# max32655 register map
Vendor: Maxim-Integrated; Series: ARMCM4; File version: 1.1
CPU: CM4 r2p1, little endian, MPU, FPU, 3 interrupt priority bits
Registers are 32-bit, read-write, reset 0x0 unless marked. A register's access mark holds for its fields unless they carry their own. Offsets are from the block's base; [hi:lo] are bit positions; {n}, {i} and the like mark numbered series.

## PT — Pulse Train
Base 0x4003C020
Same registers: PT1 0x4003C040, PT2 0x4003C060, PT3 0x4003C080
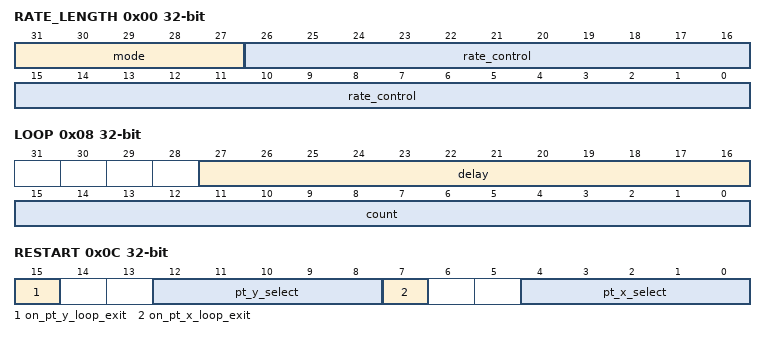
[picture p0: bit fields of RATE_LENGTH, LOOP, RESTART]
0x00 RATE_LENGTH — Pulse Train Configuration
  [31:27] mode — Pulse Train Output Mode/Train Length
    0=32_BIT (Pulse train, 32 bit pattern.); 1=SQUARE_WAVE (Square wave mode.); {v}={v}_BIT (Pulse train, {v} bit pattern.) (v=2..31)
  [26:0] rate_control — Pulse Train Enable and Rate Control. Set to 0 to disable the Pulse Train.
0x04 TRAIN — Write the repeating bit pattern that is shifted out, LSB first, when configured in Pulse Train mode. See PT_RATE_LENGTH.mode for setting the length.
0x08 LOOP — Pulse Train Loop Count
  [27:16] delay — Delay between loops of the Pulse Train in PT Peripheral Clock cycles
  [15:0] count — Number of loops for this pulse train to repeat.
0x0C RESTART — Pulse Train Auto-Restart Configuration.
  [15] on_pt_y_loop_exit — Enable Auto-Restart on PT Y Loop Exit
  [12:8] pt_y_select — Auto-Restart PT Y Select
  [7] on_pt_x_loop_exit — Enable Auto-Restart on PT X Loop Exit
  [4:0] pt_x_select — Auto-Restart PT X Select

## PTG — Pulse Train Generation
Base 0x4003C000
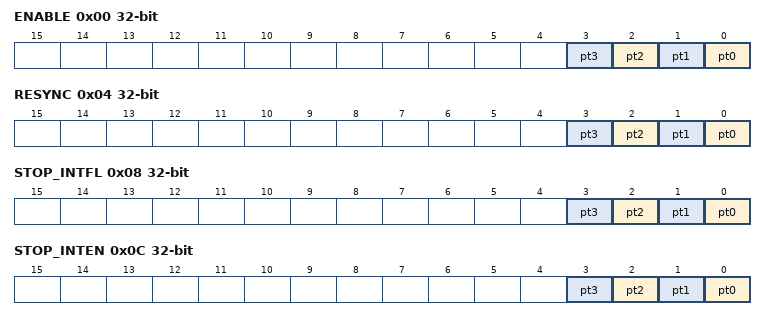
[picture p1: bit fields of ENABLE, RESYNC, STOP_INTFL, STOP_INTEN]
0x00 ENABLE — Global Enable/Disable Controls for All Pulse Trains
  [n] pt{n} (n=0..3) — Enable/Disable control for PT{n}
0x04 RESYNC — Global Resync (All Pulse Trains) Control
  [n] pt{n} (n=0..3) — Resync control for PT{n}
0x08 STOP_INTFL — Pulse Train Stop Interrupt Flags
  [n] pt{n} (n=0..3) — Pulse Train {n} Stopped Interrupt Flag
0x0C STOP_INTEN — Pulse Train Stop Interrupt Enable/Disable
  [n] pt{n} (n=0..3) — Pulse Train {n} Stopped Interrupt Enable/Disable
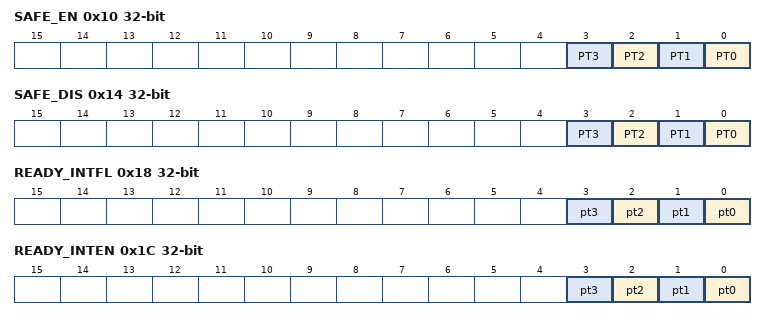
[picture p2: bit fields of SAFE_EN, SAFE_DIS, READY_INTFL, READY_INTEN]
0x10 SAFE_EN wo — Pulse Train Global Safe Enable.
  [n] PT{n} (n=0..3)
0x14 SAFE_DIS wo — Pulse Train Global Safe Disable.
  [n] PT{n} (n=0..3)
0x18 READY_INTFL — Pulse Train Ready Interrupt Flags
  [n] pt{n} (n=0..3) — Pulse Train {n} Ready Interrupt Flag
0x1C READY_INTEN — Pulse Train Ready Interrupt Enable/Disable
  [n] pt{n} (n=0..3) — Pulse Train {n} Ready Interrupt Enable/Disable

## PWRSEQ — Power Sequencer / Low Power Control Register.
Base 0x40006800
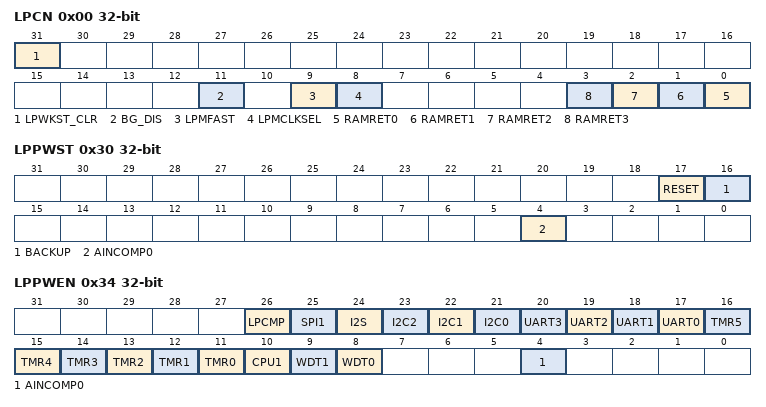
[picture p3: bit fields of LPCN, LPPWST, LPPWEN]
0x00 LPCN — Low Power Control Register.
  [31] LPWKST_CLR — Low Power Wakeup Status Register Clear
  [11] BG_DIS — Bandgap OFF. This controls the System Bandgap in DeepSleep mode.
    0=on (Bandgap is always ON.); 1=off (Bandgap is OFF in DeepSleep mode (default).)
  [9] LPMFAST — Low Power Mode Clock Select.
  [8] LPMCLKSEL — Low Power Mode APB Clock Select.
  [n] RAMRET{n} (n=0..3) — System RAM retention in BACKUP mode. These two bits are used in conjuction with RREGEN bit.
    0=dis (Disable Ram Retention.); 1=en (Enable System RAM {n} retention.)
{0x4+8i} LPWKST{i} (i=0..3) — Low Power I/O Wakeup Status Register {i}. This register indicates the low power wakeup status for GPIO{i}.
  [0] WAKEST — Wakeup IRQ flags (write ones to clear). One or more of these bits will be set when the corresponding dedicated GPIO pin (s) transition (s) from low to high or high to low. If GPIO wakeup source is selected, using PM.GPIOWKEN register, and the corresponding bit is also selected in LPWKEN register, an interrupt will be gnerated to wake up the CPU from a low power mode.
{0x8+8i} LPWKEN{i} (i=0..3) — Low Power I/O Wakeup Enable Register {i}. This register enables low power wakeup functionality for GPIO{i}.
  [30:0] WAKEEN — Enable wakeup. These bits allow wakeup from the corresponding GPIO pin (s) on transition (s) from low to high or high to low when PM.GPIOWKEN is set. Wakeup status is indicated in PPWKST register.
0x30 LPPWST — Low Power Peripheral Wakeup Status Register.
  [17] RESET — Reset Detected Wakeup Flag.
  [16] BACKUP — Backup Mode Wakeup Flag.
  [4] AINCOMP0 — Analog Input Comparator Wakeup Flag.
0x34 LPPWEN — Low Power Peripheral Wakeup Enable Register.
  [26] LPCMP — LPCMP Wakeup Enable. This bit allows wakeup from the LPCMP.
  [25] SPI1 — SPI1 Wakeup Enable. This bit allows wakeup from the SPI1.
  [24] I2S — I2S Wakeup Enable. This bit allows wakeup from the I2S.
  [23] I2C2 — I2C2 Wakeup Enable. This bit allows wakeup from the I2C2.
  [22] I2C1 — I2C1 Wakeup Enable. This bit allows wakeup from the I2C1.
  [21] I2C0 — I2C0 Wakeup Enable. This bit allows wakeup from the I2C0.
  [n+17] UART{n} (n=0..3) — UART{n} Wakeup Enable. This bit allows wakeup from the UART{n}.
  [n+11] TMR{n} (n=0..5) — TMR{n} Wakeup Enable. This bit allows wakeup from the TMR{n}.
  [10] CPU1 — CPU1 Wakeup Enable. This bit allows wakeup from the CPU1.
  [9] WDT1 — WDT1 Wakeup Enable. This bit allows wakeup from the WDT1.
  [8] WDT0 — WDT0 Wakeup Enable. This bit allows wakeup from the WDT0.
  [4] AINCOMP0 — AINCOMP0 Wakeup Enable. This bit allows wakeup from the AINCOMP0.
0x44 VBTLEPD — Low-Power VBTLE Power Down Register.
  [1] BTLE — Power Down SIMO VREGO_D.
0x48 GP0 — General Purpose Register 0
0x4C GP1 — General Purpose Register 1
